# SAM9X60 device description
Architecture: ARM926EJS; Family: SAM9; Series: SAM9X
Registers are 32-bit, read-write, no defined reset value unless marked. A register's access mark holds for its fields unless they carry their own. Offsets are from the block's base; [hi:lo] are bit positions; {n}, {i} and the like mark numbered series.

## AIC — Advanced Interrupt Controller
Instances: AIC 0xFFFFF100
0x00 AIC_SSR — Source Select Register
  [6:0] INTSEL — Interrupt Line Selection
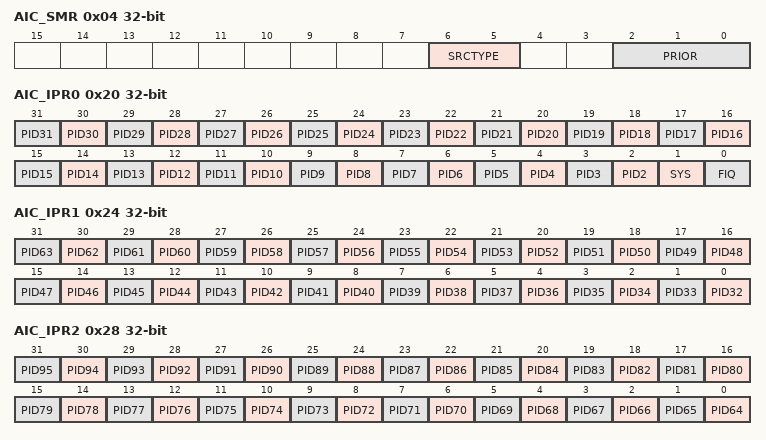
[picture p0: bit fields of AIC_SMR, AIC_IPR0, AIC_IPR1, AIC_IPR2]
0x04 AIC_SMR — Source Mode Register
  [6:5] SRCTYPE — Interrupt Source Type
    0=INT_LEVEL_SENSITIVE (High-level sensitive for internal source. Low-level sensitive for external source); 1=EXT_NEGATIVE_EDGE (Negative-edge triggered for external source); 2=EXT_HIGH_LEVEL (High-level sensitive for internal source. High-level sensitive for external source); 3=EXT_POSITIVE_EDGE (Positive-edge triggered for external source)
  [2:0] PRIOR — Priority Level
    0=MINIMUM (Minimum priority); 1=VERY_LOW (Very low priority); 2=LOW (Low priority); 3=MEDIUM_LOW (Medium priority); 4=MEDIUM_HIGH (Medium-high priority); 5=HIGH (High priority); 6=VERY_HIGH (Very high priority); 7=MAXIMUM (Maximum priority)
0x08 AIC_SVR — Source Vector Register
  [31:0] VECTOR — Source Vector
0x10 AIC_IVR ro — Interrupt Vector Register
  [31:0] IRQV
0x14 AIC_FVR ro — FIQ Vector Register
  [31:0] FIQV
0x18 AIC_ISR ro — Interrupt Status Register
  [6:0] IRQID — Current Interrupt Identifier
0x20 AIC_IPR0 ro — Interrupt Pending Register 0
  [n] PID{n} (n=2..31) — Interrupt Pending
  [1] SYS — Interrupt Pending
  [0] FIQ — Interrupt Pending
0x24 AIC_IPR1 ro — Interrupt Pending Register 1
  [n-32] PID{n} (n=32..63) — Interrupt Pending
0x28 AIC_IPR2 ro — Interrupt Pending Register 2
  [n-64] PID{n} (n=64..95) — Interrupt Pending
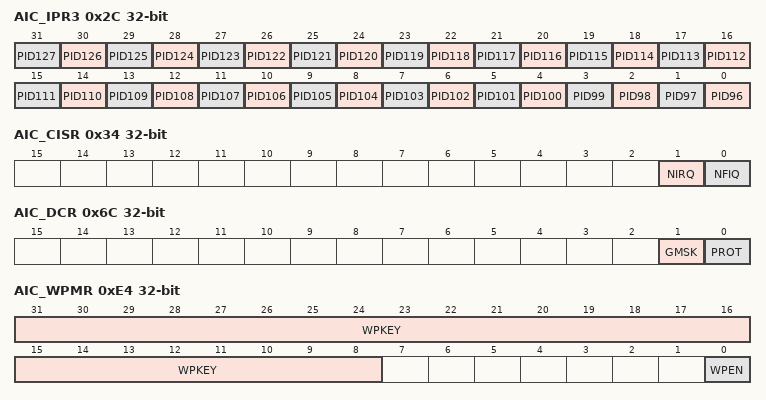
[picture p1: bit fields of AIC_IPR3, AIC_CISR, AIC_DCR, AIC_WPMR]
0x2C AIC_IPR3 ro — Interrupt Pending Register 3
  [n-96] PID{n} (n=96..127) — Interrupt Pending
0x30 AIC_IMR ro — Interrupt Mask Register
  [0] INTM — Interrupt Mask
0x34 AIC_CISR ro — Core Interrupt Status Register
  [1] NIRQ — NIRQ Status
  [0] NFIQ — NFIQ Status
0x38 AIC_EOICR wo — End of Interrupt Command Register
  [0] ENDIT — Interrupt Processing Complete Command
0x3C AIC_SPU — Spurious Interrupt Vector Register
  [31:0] SIVR
0x40 AIC_IECR wo — Interrupt Enable Command Register
  [0] INTEN — Interrupt Enable
0x44 AIC_IDCR wo — Interrupt Disable Command Register
  [0] INTD — Interrupt Disable
0x48 AIC_ICCR wo — Interrupt Clear Command Register
  [0] INTCLR — Interrupt Clear
0x4C AIC_ISCR wo — Interrupt Set Command Register
  [0] INTSET — Interrupt Set
0x50 AIC_FFER wo — Fast Forcing Enable Register
  [0] FFEN — Fast Forcing Enable
0x54 AIC_FFDR wo — Fast Forcing Disable Register
  [0] FFDIS — Fast Forcing Disable
0x58 AIC_FFSR ro — Fast Forcing Status Register
  [0] FFS — Fast Forcing Status
0x60 AIC_SVRRER wo — SVR Return Enable Register
  [0] SVRREN — SVR Return Enable
0x64 AIC_SVRRDR wo — SVR Return Disable Register
  [0] SVRRDIS — SVR Return Disable
0x68 AIC_SVRRSR ro — SVR Return Status Register
  [0] SVRRS — SVR Return Status
0x6C AIC_DCR — Debug Control Register
  [1] GMSK — General Interrupt Mask
  [0] PROT — Protection Mode
0xE4 AIC_WPMR — Write Protection Mode Register
  [31:8] WPKEY — Write Protection Key
    0x414943=PASSWD (Writing any other value in this field aborts the write operation of the WPEN bit.Always reads as 0.)
  [0] WPEN — Write Protection Enable
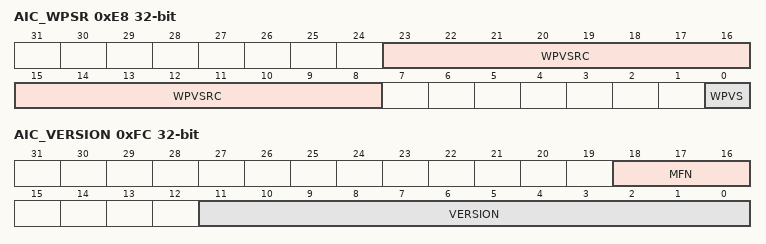
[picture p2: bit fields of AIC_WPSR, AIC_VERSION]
0xE8 AIC_WPSR ro — Write Protection Status Register
  [23:8] WPVSRC — Write Protection Violation Source
  [0] WPVS — Write Protection Violation Status
0xFC AIC_VERSION ro
  [18:16] MFN — Metal Fix Number
  [11:0] VERSION — Version of the Hardware Module

## BSC — Boot Sequence Controller
Instances: BSC 0xFFFFFE54
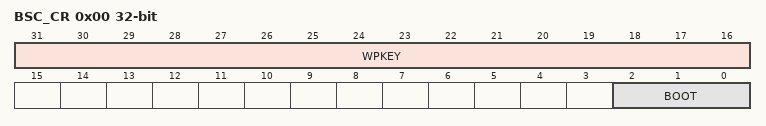
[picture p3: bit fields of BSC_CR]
0x00 BSC_CR — Boot Sequence Controller Configuration Register
  [31:16] WPKEY — Write Protection Key (Write-only)
    0x6683=PASSWD (Writing any other value in this field aborts the write operation of the BOOT field.Always reads as 0.)
  [2:0] BOOT — Boot Media Sequence

## Notices in the file
Copyright (c) 2017 Microchip Technology Inc.
SPDX-License-Identifier: Apache-2.0
Licensed under the Apache License, Version 2.0 (the "License");
you may not use this file except in compliance with the License.
You may obtain a copy of the License at
http://www.apache.org/licenses/LICENSE-2.0
Unless required by applicable law or agreed to in writing, software
distributed under the License is distributed on an "AS IS" BASIS,
WITHOUT WARRANTIES OR CONDITIONS OF ANY KIND, either express or implied.
See the License for the specific language governing permissions and
limitations under the License.
